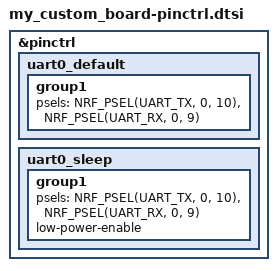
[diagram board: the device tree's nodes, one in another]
/*
 * @bried my_custom_board board device tree file
 */

&pinctrl {
  uart0_default: uart0_default {
    group1 {
      psels = <NRF_PSEL(UART_TX, 0, 10)>,
              <NRF_PSEL(UART_RX, 0, 9)>;
    };
  };

  uart0_sleep: uart0_sleep {
    group1 {
      psels = <NRF_PSEL(UART_TX, 0, 10)>,
              <NRF_PSEL(UART_RX, 0, 9)>;
      low-power-enable;
    };
  };
};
